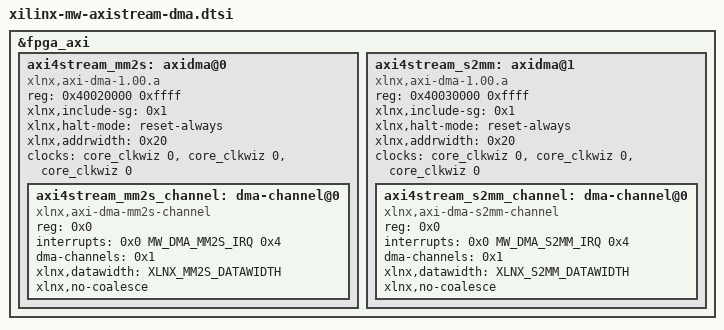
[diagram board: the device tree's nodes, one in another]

#include "xilinx-mw-axistream-dma.h"

&fpga_axi {
	axi4stream_mm2s:axidma@0 {
		#dma-cells = <0x1>;
		#address-cells = <1>;
		#size-cells = <0>;
		compatible = "xlnx,axi-dma-1.00.a";
		reg = <0x40020000 0xffff>;
		xlnx,include-sg = <0x1>;
		xlnx,halt-mode = "reset-always";
		xlnx,addrwidth = <0x20>;
		clocks = <&core_clkwiz 0>, <&core_clkwiz 0>, <&core_clkwiz 0>;
		clock-names = "s_axi_lite_aclk", "m_axi_sg_aclk", "m_axi_mm2s_aclk";
		axi4stream_mm2s_channel: dma-channel@0  {
			reg = <0x0>;
			compatible = "xlnx,axi-dma-mm2s-channel";
			interrupts = <0x0 MW_DMA_MM2S_IRQ 0x4>;
			dma-channels = <0x1>;
			xlnx,datawidth = XLNX_MM2S_DATAWIDTH;
			xlnx,no-coalesce;
		};
	};
	axi4stream_s2mm:axidma@1 {
		#dma-cells = <0x1>;
		#address-cells = <1>;
		#size-cells = <0>;
		compatible = "xlnx,axi-dma-1.00.a";
		reg = <0x40030000 0xffff>;
		xlnx,include-sg = <0x1>;
		xlnx,halt-mode = "reset-always";
		xlnx,addrwidth = <0x20>;
		clocks = <&core_clkwiz 0>, <&core_clkwiz 0>, <&core_clkwiz 0>;
		clock-names = "s_axi_lite_aclk", "m_axi_sg_aclk", "m_axi_s2mm_aclk";
		axi4stream_s2mm_channel: dma-channel@0 {
			reg = <0x0>;
			compatible = "xlnx,axi-dma-s2mm-channel";
			interrupts = <0x0 MW_DMA_S2MM_IRQ 0x4>;
			dma-channels = <0x1>;			
			xlnx,datawidth = XLNX_S2MM_DATAWIDTH;
			xlnx,no-coalesce;
		};
	};
};

